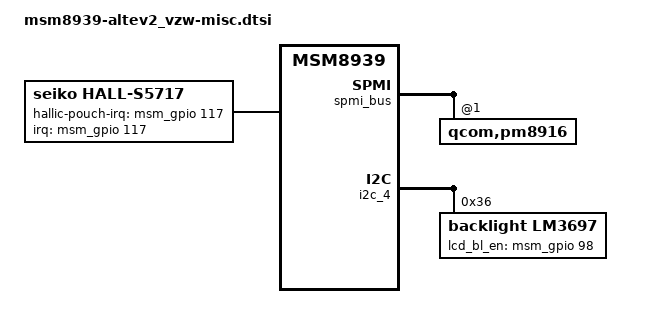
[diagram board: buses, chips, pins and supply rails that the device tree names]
/* Copyright (c) 2012, Code Aurora Forum. All rights reserved.
 *
 * This program is free software; you can redistribute it and/or modify
 * it under the terms of the GNU General Public License version 2 and
 * only version 2 as published by the Free Software Foundation.
 *
 * This program is distributed in the hope that it will be useful,
 * but WITHOUT ANY WARRANTY; without even the implied warranty of
 * MERCHANTABILITY or FITNESS FOR A PARTICULAR PURPOSE.  See the
 * GNU General Public License for more details.
 */

&spmi_bus {
	qcom,pm8916@1 {
		qcom,vibrator@c000 {
			status = "okay";
			qcom,vib-timeout-ms = <15000>;
			qcom,vib-vtg-level-mV = <3100>;
		};
	};
};

&soc {
	hall-s5717 {
		compatible = "seiko,hall-s5717";
		interrupt-parent = <&msm_gpio>;
		interrupts = <117 0x0>;
		hallic-pouch-irq-gpio = <&msm_gpio 117 0x00>;

		pinctrl-names = "pmx_hall_ic_active","pmx_hall_ic_suspend";
		pinctrl-0 = <&hall_ic_int_active>;
		pinctrl-1 = <&hall_ic_int_suspend>;
		status = "ok";
	};
};

&i2c_4 {
	lm3697@36 {
		compatible = "backlight,lm3697";
		status = "ok";
		reg = <0x36>;
		lm3697,lcd_bl_en = <&msm_gpio 98 0x00>;
		pinctrl-names = "default", "sleep";
		pinctrl-0 = <&bklight_en_active>;
		pinctrl-1 = <&bklight_en_suspend>;
		lm3697,max_current = <0x18>;
		lm3697,min_brightness = <0x01>;
		lm3697,default_brightness = <0xA8>;
		lm3697,max_brightness = <0xFF>;
		lm3697,enable_pwm = <0>;
		lm3697,blmap_size = <256>;
		lm3697,blmap = <
				2 2 2 2 2 2 2 2 2 2 
				2 2 2 2 2 2 2 2 2 2
				3 3 3 3 3 3 3 3 3 3
				3 3 3 3 3 3 3 3 4 4
				4 5 5 5 5 6 6 6 6 7

				7 7 7 7 8 8 8 8 9 9
				9 9 9 9 11 11 11 12 12 12
				13 13 13 14 14 14 15 15 15 16
				16 16 17 17 17 18 18 18 18 19
				19 19 19 19 19 19 19 20 21 22

				23 24 25 26 27 28 30 32 33 34
				34 34 35 36 38 40 42 44 46 47
				48 49 49 50 51 51 52 52 53 53
				53 54 54 54 54 54 56 58 61 63
				65 66 67 68 70 69 71 72 73 74

				75 76 77 78 79 80 80 80 80 80
				83 87 91 92 94 94 94 97 98 99
				100 101 102 103 104 107 108 109 110 110
				111 112 113 113 113 113 117 120 124 128
				129 130 131 131 133 135 137 139 140 141

				142 144 146 147 151 153 153 153 153 153
				155 160 164 166 168 169 170 171 173 176
				179 182 184 186 188 190 192 194 196 198
				200 200 200 200 200 209 213 215 217 218
				219 220 221 224 227 231 236 239 241 243

				244 245 246 250 252 255>;

	};
};

